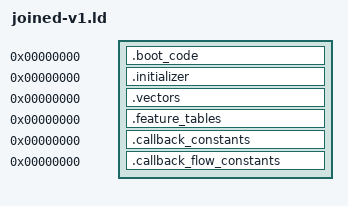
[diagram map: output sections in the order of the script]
OUTPUT_ARCH(riscv)
SECTIONS
{
 .boot_code 0 : SUBALIGN(2) { *(.boot_code)
  *(.text.tsl9_rom_dependency_external_b6ea)
  *(.text.tsl9_rom_dependency_external_d05c)
  *(.text.tsl9_rom_dependency_external_10816)
  *(.text.tsl9_state_output_block_10818)
  *(.text.tsl9_state_output_block_1081a)
 }
 .initializer 0 : SUBALIGN(4) { *(.initializer) }
 .vectors 0 : SUBALIGN(4) { *(.vectors) }
 .feature_tables 0 : SUBALIGN(4) { *(.feature_tables) }
 .callback_constants 0 : SUBALIGN(4) { *(.callback_constants) }
 .callback_flow_constants 0 : SUBALIGN(4) { *(.callback_flow_constants) }
 /DISCARD/ : { *(.comment) *(.riscv.attributes) *(.llvm_addrsig) }
}
